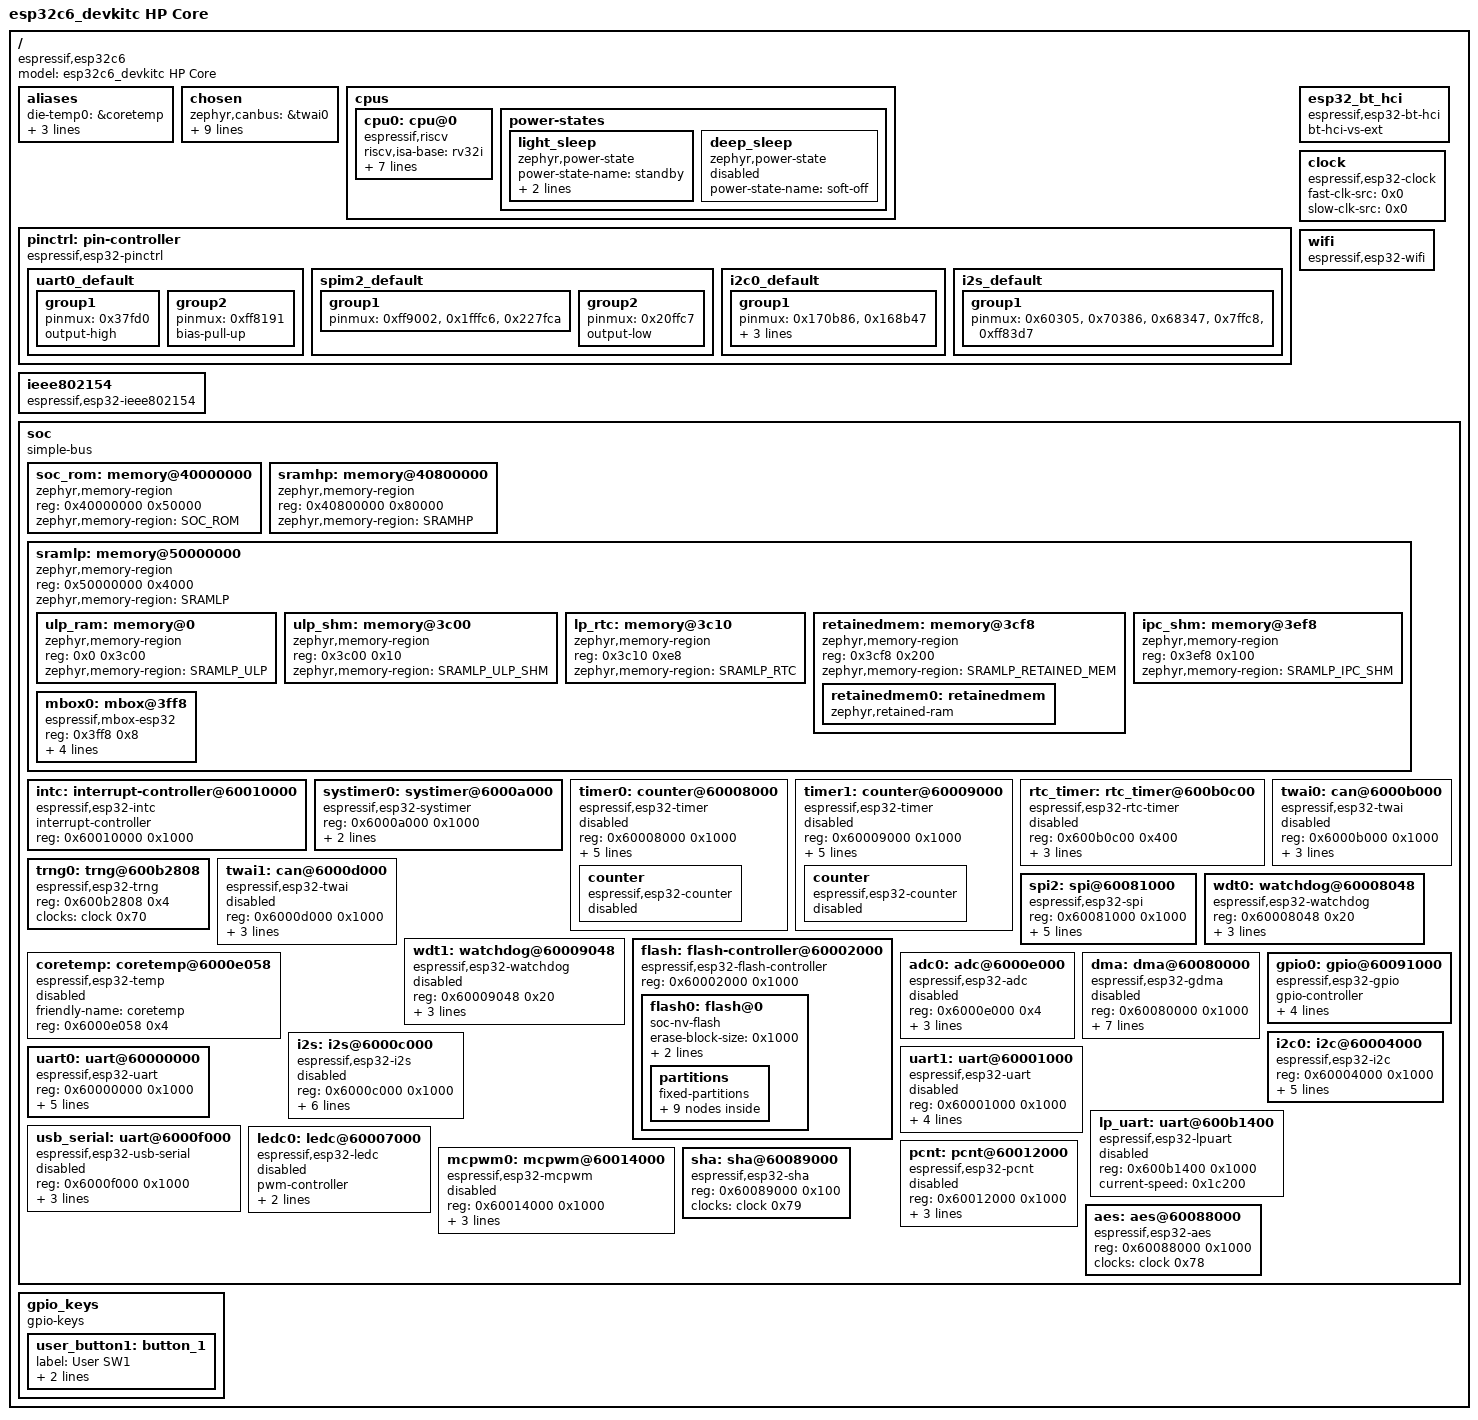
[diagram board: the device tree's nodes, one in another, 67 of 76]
/dts-v1/;

/* node '/' defined in zephyr/dts/riscv/espressif/esp32c6/esp32c6_common.dtsi:16 */
/ {
	#address-cells = < 0x1 >;          /* in zephyr/dts/riscv/espressif/esp32c6/esp32c6_common.dtsi:17 */
	#size-cells = < 0x1 >;             /* in zephyr/dts/riscv/espressif/esp32c6/esp32c6_common.dtsi:18 */
	model = "esp32c6_devkitc HP Core"; /* in zephyr/boards/espressif/esp32c6_devkitc/esp32c6_devkitc_hpcore.dts:15 */
	compatible = "espressif,esp32c6";  /* in zephyr/boards/espressif/esp32c6_devkitc/esp32c6_devkitc_hpcore.dts:16 */

	/* node '/aliases' defined in zephyr/dts/riscv/espressif/esp32c6/esp32c6_common.dtsi:20 */
	aliases {
		die-temp0 = &coretemp;             /* in zephyr/dts/riscv/espressif/esp32c6/esp32c6_common.dtsi:21 */
		retainedmemdevice = &retainedmem0; /* in zephyr/dts/riscv/espressif/esp32c6/esp32c6_common.dtsi:22 */
		sw0 = &user_button1;               /* in zephyr/boards/espressif/esp32c6_devkitc/esp32c6_devkitc_hpcore.dts:28 */
		watchdog0 = &wdt0;                 /* in zephyr/boards/espressif/esp32c6_devkitc/esp32c6_devkitc_hpcore.dts:29 */
	};

	/* node '/chosen' defined in zephyr/dts/riscv/espressif/esp32c6/esp32c6_common.dtsi:25 */
	chosen {
		zephyr,canbus = &twai0;                   /* in zephyr/dts/riscv/espressif/esp32c6/esp32c6_common.dtsi:26 */
		zephyr,entropy = &trng0;                  /* in zephyr/dts/riscv/espressif/esp32c6/esp32c6_common.dtsi:27 */
		zephyr,flash-controller = &flash;         /* in zephyr/dts/riscv/espressif/esp32c6/esp32c6_common.dtsi:28 */
		zephyr,bt-hci = &esp32_bt_hci;            /* in zephyr/dts/riscv/espressif/esp32c6/esp32c6_common.dtsi:29 */
		zephyr,sram = &sramhp;                    /* in zephyr/boards/espressif/esp32c6_devkitc/esp32c6_devkitc_hpcore.dts:19 */
		zephyr,console = &uart0;                  /* in zephyr/boards/espressif/esp32c6_devkitc/esp32c6_devkitc_hpcore.dts:20 */
		zephyr,shell-uart = &uart0;               /* in zephyr/boards/espressif/esp32c6_devkitc/esp32c6_devkitc_hpcore.dts:21 */
		zephyr,flash = &flash0;                   /* in zephyr/boards/espressif/esp32c6_devkitc/esp32c6_devkitc_hpcore.dts:22 */
		zephyr,code-partition = &slot0_partition; /* in zephyr/boards/espressif/esp32c6_devkitc/esp32c6_devkitc_hpcore.dts:23 */
		zephyr,ieee802154 = &ieee802154;          /* in zephyr/boards/espressif/esp32c6_devkitc/esp32c6_devkitc_hpcore.dts:24 */
	};

	/* node '/cpus' defined in zephyr/dts/riscv/espressif/esp32c6/esp32c6_common.dtsi:32 */
	cpus {
		#address-cells = < 0x1 >; /* in zephyr/dts/riscv/espressif/esp32c6/esp32c6_common.dtsi:33 */
		#size-cells = < 0x0 >;    /* in zephyr/dts/riscv/espressif/esp32c6/esp32c6_common.dtsi:34 */

		/* node '/cpus/cpu@0' defined in zephyr/dts/riscv/espressif/esp32c6/esp32c6_common.dtsi:36 */
		cpu0: cpu@0 {
			device_type = "cpu";                             /* in zephyr/dts/riscv/espressif/esp32c6/esp32c6_common.dtsi:37 */
			compatible = "espressif,riscv",
			             "riscv";                            /* in zephyr/dts/riscv/espressif/esp32c6/esp32c6_common.dtsi:38 */
			riscv,isa-base = "rv32i";                        /* in zephyr/dts/riscv/espressif/esp32c6/esp32c6_common.dtsi:39 */
			riscv,isa-extensions = "i",
			                       "m",
			                       "a",
			                       "c",
			                       "zicsr",
			                       "zifencei";               /* in zephyr/dts/riscv/espressif/esp32c6/esp32c6_common.dtsi:40 */
			reg = < 0x0 >;                                   /* in zephyr/dts/riscv/espressif/esp32c6/esp32c6_common.dtsi:41 */
			cpu-power-states = < &light_sleep &deep_sleep >; /* in zephyr/dts/riscv/espressif/esp32c6/esp32c6_common.dtsi:42 */
			clock-source = < 0x1 >;                          /* in zephyr/dts/riscv/espressif/esp32c6/esp32c6_common.dtsi:43 */
			clock-frequency = < 0x9896800 >;                 /* in zephyr/dts/riscv/espressif/esp32c6/esp32c6_common.dtsi:44 */
			xtal-freq = < 0x2625a00 >;                       /* in zephyr/dts/riscv/espressif/esp32c6/esp32c6_common.dtsi:45 */
		};

		/* node '/cpus/power-states' defined in zephyr/dts/riscv/espressif/esp32c6/esp32c6_common.dtsi:48 */
		power-states {

			/* node '/cpus/power-states/light_sleep' defined in zephyr/dts/riscv/espressif/esp32c6/esp32c6_common.dtsi:49 */
			light_sleep: light_sleep {
				compatible = "zephyr,power-state"; /* in zephyr/dts/riscv/espressif/esp32c6/esp32c6_common.dtsi:50 */
				power-state-name = "standby";      /* in zephyr/dts/riscv/espressif/esp32c6/esp32c6_common.dtsi:51 */
				min-residency-us = < 0x9c4 >;      /* in zephyr/dts/riscv/espressif/esp32c6/esp32c6_common.dtsi:52 */
				exit-latency-us = < 0x32 >;        /* in zephyr/dts/riscv/espressif/esp32c6/esp32c6_common.dtsi:53 */
				phandle = < 0x1 >;                 /* in zephyr/dts/riscv/espressif/esp32c6/esp32c6_common.dtsi:42 */
			};

			/* node '/cpus/power-states/deep_sleep' defined in zephyr/dts/riscv/espressif/esp32c6/esp32c6_common.dtsi:56 */
			deep_sleep: deep_sleep {
				compatible = "zephyr,power-state"; /* in zephyr/dts/riscv/espressif/esp32c6/esp32c6_common.dtsi:60 */
				power-state-name = "soft-off";     /* in zephyr/dts/riscv/espressif/esp32c6/esp32c6_common.dtsi:61 */
				status = "disabled";               /* in zephyr/dts/riscv/espressif/esp32c6/esp32c6_common.dtsi:62 */
				phandle = < 0x2 >;                 /* in zephyr/dts/riscv/espressif/esp32c6/esp32c6_common.dtsi:42 */
			};
		};
	};

	/* node '/pin-controller' defined in zephyr/dts/riscv/espressif/esp32c6/esp32c6_common.dtsi:67 */
	pinctrl: pin-controller {
		compatible = "espressif,esp32-pinctrl"; /* in zephyr/dts/riscv/espressif/esp32c6/esp32c6_common.dtsi:68 */
		status = "okay";                        /* in zephyr/dts/riscv/espressif/esp32c6/esp32c6_common.dtsi:69 */

		/* node '/pin-controller/uart0_default' defined in zephyr/boards/espressif/esp32c6_devkitc/esp32c6_devkitc_hpcore-pinctrl.dtsi:12 */
		uart0_default: uart0_default {
			phandle = < 0xa >; /* in zephyr/boards/espressif/esp32c6_devkitc/esp32c6_devkitc_hpcore.dts:46 */

			/* node '/pin-controller/uart0_default/group1' defined in zephyr/boards/espressif/esp32c6_devkitc/esp32c6_devkitc_hpcore-pinctrl.dtsi:13 */
			group1 {
				pinmux = < 0x37fd0 >; /* in zephyr/boards/espressif/esp32c6_devkitc/esp32c6_devkitc_hpcore-pinctrl.dtsi:14 */
				output-high;          /* in zephyr/boards/espressif/esp32c6_devkitc/esp32c6_devkitc_hpcore-pinctrl.dtsi:15 */
			};

			/* node '/pin-controller/uart0_default/group2' defined in zephyr/boards/espressif/esp32c6_devkitc/esp32c6_devkitc_hpcore-pinctrl.dtsi:18 */
			group2 {
				pinmux = < 0xff8191 >; /* in zephyr/boards/espressif/esp32c6_devkitc/esp32c6_devkitc_hpcore-pinctrl.dtsi:19 */
				bias-pull-up;          /* in zephyr/boards/espressif/esp32c6_devkitc/esp32c6_devkitc_hpcore-pinctrl.dtsi:20 */
			};
		};

		/* node '/pin-controller/spim2_default' defined in zephyr/boards/espressif/esp32c6_devkitc/esp32c6_devkitc_hpcore-pinctrl.dtsi:24 */
		spim2_default: spim2_default {
			phandle = < 0x6 >; /* in zephyr/boards/espressif/esp32c6_devkitc/esp32c6_devkitc_hpcore.dts:70 */

			/* node '/pin-controller/spim2_default/group1' defined in zephyr/boards/espressif/esp32c6_devkitc/esp32c6_devkitc_hpcore-pinctrl.dtsi:25 */
			group1 {
				pinmux = < 0xff9002 >,
				         < 0x1fffc6 >,
				         < 0x227fca >; /* in zephyr/boards/espressif/esp32c6_devkitc/esp32c6_devkitc_hpcore-pinctrl.dtsi:26 */
			};

			/* node '/pin-controller/spim2_default/group2' defined in zephyr/boards/espressif/esp32c6_devkitc/esp32c6_devkitc_hpcore-pinctrl.dtsi:31 */
			group2 {
				pinmux = < 0x20ffc7 >; /* in zephyr/boards/espressif/esp32c6_devkitc/esp32c6_devkitc_hpcore-pinctrl.dtsi:32 */
				output-low;            /* in zephyr/boards/espressif/esp32c6_devkitc/esp32c6_devkitc_hpcore-pinctrl.dtsi:33 */
			};
		};

		/* node '/pin-controller/i2c0_default' defined in zephyr/boards/espressif/esp32c6_devkitc/esp32c6_devkitc_hpcore-pinctrl.dtsi:37 */
		i2c0_default: i2c0_default {
			phandle = < 0x7 >; /* in zephyr/boards/espressif/esp32c6_devkitc/esp32c6_devkitc_hpcore.dts:57 */

			/* node '/pin-controller/i2c0_default/group1' defined in zephyr/boards/espressif/esp32c6_devkitc/esp32c6_devkitc_hpcore-pinctrl.dtsi:38 */
			group1 {
				pinmux = < 0x170b86 >,
				         < 0x168b47 >; /* in zephyr/boards/espressif/esp32c6_devkitc/esp32c6_devkitc_hpcore-pinctrl.dtsi:39 */
				bias-pull-up;          /* in zephyr/boards/espressif/esp32c6_devkitc/esp32c6_devkitc_hpcore-pinctrl.dtsi:41 */
				drive-open-drain;      /* in zephyr/boards/espressif/esp32c6_devkitc/esp32c6_devkitc_hpcore-pinctrl.dtsi:42 */
				output-high;           /* in zephyr/boards/espressif/esp32c6_devkitc/esp32c6_devkitc_hpcore-pinctrl.dtsi:43 */
			};
		};

		/* node '/pin-controller/i2s_default' defined in zephyr/boards/espressif/esp32c6_devkitc/esp32c6_devkitc_hpcore-pinctrl.dtsi:47 */
		i2s_default: i2s_default {
			phandle = < 0x9 >; /* in zephyr/boards/espressif/esp32c6_devkitc/esp32c6_devkitc_hpcore.dts:62 */

			/* node '/pin-controller/i2s_default/group1' defined in zephyr/boards/espressif/esp32c6_devkitc/esp32c6_devkitc_hpcore-pinctrl.dtsi:48 */
			group1 {
				pinmux = < 0x60305 >,
				         < 0x70386 >,
				         < 0x68347 >,
				         < 0x7ffc8 >,
				         < 0xff83d7 >; /* in zephyr/boards/espressif/esp32c6_devkitc/esp32c6_devkitc_hpcore-pinctrl.dtsi:49 */
			};
		};
	};

	/* node '/esp32_bt_hci' defined in zephyr/dts/riscv/espressif/esp32c6/esp32c6_common.dtsi:72 */
	esp32_bt_hci: esp32_bt_hci {
		compatible = "espressif,esp32-bt-hci"; /* in zephyr/dts/riscv/espressif/esp32c6/esp32c6_common.dtsi:73 */
		bt-hci-vs-ext;                         /* in zephyr/dts/riscv/espressif/esp32c6/esp32c6_common.dtsi:74 */
		status = "okay";                       /* in zephyr/boards/espressif/esp32c6_devkitc/esp32c6_devkitc_hpcore.dts:91 */
	};

	/* node '/clock' defined in zephyr/dts/riscv/espressif/esp32c6/esp32c6_common.dtsi:78 */
	clock: clock {
		compatible = "espressif,esp32-clock"; /* in zephyr/dts/riscv/espressif/esp32c6/esp32c6_common.dtsi:79 */
		fast-clk-src = < 0x0 >;               /* in zephyr/dts/riscv/espressif/esp32c6/esp32c6_common.dtsi:80 */
		slow-clk-src = < 0x0 >;               /* in zephyr/dts/riscv/espressif/esp32c6/esp32c6_common.dtsi:81 */
		#clock-cells = < 0x1 >;               /* in zephyr/dts/riscv/espressif/esp32c6/esp32c6_common.dtsi:82 */
		status = "okay";                      /* in zephyr/dts/riscv/espressif/esp32c6/esp32c6_common.dtsi:83 */
		phandle = < 0x5 >;                    /* in zephyr/dts/riscv/espressif/esp32c6/esp32c6_common.dtsi:202 */
	};

	/* node '/wifi' defined in zephyr/dts/riscv/espressif/esp32c6/esp32c6_common.dtsi:86 */
	wifi: wifi {
		compatible = "espressif,esp32-wifi"; /* in zephyr/dts/riscv/espressif/esp32c6/esp32c6_common.dtsi:87 */
		status = "okay";                     /* in zephyr/boards/espressif/esp32c6_devkitc/esp32c6_devkitc_hpcore.dts:83 */
	};

	/* node '/ieee802154' defined in zephyr/dts/riscv/espressif/esp32c6/esp32c6_common.dtsi:91 */
	ieee802154: ieee802154 {
		compatible = "espressif,esp32-ieee802154"; /* in zephyr/dts/riscv/espressif/esp32c6/esp32c6_common.dtsi:92 */
		status = "okay";                           /* in zephyr/boards/espressif/esp32c6_devkitc/esp32c6_devkitc_hpcore.dts:87 */
	};

	/* node '/soc' defined in zephyr/dts/riscv/espressif/esp32c6/esp32c6_common.dtsi:96 */
	soc {
		#address-cells = < 0x1 >;  /* in zephyr/dts/riscv/espressif/esp32c6/esp32c6_common.dtsi:97 */
		#size-cells = < 0x1 >;     /* in zephyr/dts/riscv/espressif/esp32c6/esp32c6_common.dtsi:98 */
		compatible = "simple-bus"; /* in zephyr/dts/riscv/espressif/esp32c6/esp32c6_common.dtsi:99 */
		ranges;                    /* in zephyr/dts/riscv/espressif/esp32c6/esp32c6_common.dtsi:100 */

		/* node '/soc/memory@40000000' defined in zephyr/dts/riscv/espressif/esp32c6/esp32c6_common.dtsi:107 */
		soc_rom: memory@40000000 {
			compatible = "zephyr,memory-region"; /* in zephyr/dts/riscv/espressif/esp32c6/esp32c6_common.dtsi:108 */
			reg = < 0x40000000 0x50000 >;        /* in zephyr/dts/riscv/espressif/esp32c6/esp32c6_common.dtsi:109 */
			zephyr,memory-region = "SOC_ROM";    /* in zephyr/dts/riscv/espressif/esp32c6/esp32c6_common.dtsi:110 */
		};

		/* node '/soc/memory@40800000' defined in zephyr/dts/riscv/espressif/esp32c6/esp32c6_common.dtsi:113 */
		sramhp: memory@40800000 {
			compatible = "zephyr,memory-region",
			             "mmio-sram";            /* in zephyr/dts/riscv/espressif/esp32c6/esp32c6_common.dtsi:114 */
			reg = < 0x40800000 0x80000 >;        /* in zephyr/dts/riscv/espressif/esp32c6/esp32c6_common.dtsi:115 */
			zephyr,memory-region = "SRAMHP";     /* in zephyr/dts/riscv/espressif/esp32c6/esp32c6_common.dtsi:116 */
		};

		/* node '/soc/memory@50000000' defined in zephyr/dts/riscv/espressif/esp32c6/esp32c6_common.dtsi:119 */
		sramlp: memory@50000000 {
			#address-cells = < 0x1 >;            /* in zephyr/dts/riscv/espressif/esp32c6/esp32c6_common.dtsi:120 */
			#size-cells = < 0x1 >;               /* in zephyr/dts/riscv/espressif/esp32c6/esp32c6_common.dtsi:121 */
			compatible = "zephyr,memory-region",
			             "mmio-sram";            /* in zephyr/dts/riscv/espressif/esp32c6/esp32c6_common.dtsi:122 */
			reg = < 0x50000000 0x4000 >;         /* in zephyr/dts/riscv/espressif/esp32c6/esp32c6_common.dtsi:123 */
			zephyr,memory-region = "SRAMLP";     /* in zephyr/dts/riscv/espressif/esp32c6/esp32c6_common.dtsi:124 */
			ranges = < 0x0 0x50000000 0x4000 >;  /* in zephyr/dts/riscv/espressif/esp32c6/esp32c6_common.dtsi:125 */

			/* node '/soc/memory@50000000/memory@0' defined in zephyr/dts/riscv/espressif/esp32c6/esp32c6_common.dtsi:127 */
			ulp_ram: memory@0 {
				compatible = "zephyr,memory-region",
				             "mmio-sram";            /* in zephyr/dts/riscv/espressif/esp32c6/esp32c6_common.dtsi:128 */
				reg = < 0x0 0x3c00 >;                /* in zephyr/dts/riscv/espressif/esp32c6/esp32c6_common.dtsi:129 */
				zephyr,memory-region = "SRAMLP_ULP"; /* in zephyr/dts/riscv/espressif/esp32c6/esp32c6_common.dtsi:130 */
			};

			/* node '/soc/memory@50000000/memory@3c00' defined in zephyr/dts/riscv/espressif/esp32c6/esp32c6_common.dtsi:133 */
			ulp_shm: memory@3c00 {
				compatible = "zephyr,memory-region",
				             "mmio-sram";                /* in zephyr/dts/riscv/espressif/esp32c6/esp32c6_common.dtsi:134 */
				reg = < 0x3c00 0x10 >;                   /* in zephyr/dts/riscv/espressif/esp32c6/esp32c6_common.dtsi:135 */
				zephyr,memory-region = "SRAMLP_ULP_SHM"; /* in zephyr/dts/riscv/espressif/esp32c6/esp32c6_common.dtsi:136 */
			};

			/* node '/soc/memory@50000000/memory@3c10' defined in zephyr/dts/riscv/espressif/esp32c6/esp32c6_common.dtsi:139 */
			lp_rtc: memory@3c10 {
				compatible = "zephyr,memory-region",
				             "mmio-sram";            /* in zephyr/dts/riscv/espressif/esp32c6/esp32c6_common.dtsi:140 */
				reg = < 0x3c10 0xe8 >;               /* in zephyr/dts/riscv/espressif/esp32c6/esp32c6_common.dtsi:141 */
				zephyr,memory-region = "SRAMLP_RTC"; /* in zephyr/dts/riscv/espressif/esp32c6/esp32c6_common.dtsi:142 */
			};

			/* node '/soc/memory@50000000/memory@3cf8' defined in zephyr/dts/riscv/espressif/esp32c6/esp32c6_common.dtsi:145 */
			retainedmem: memory@3cf8 {
				compatible = "zephyr,memory-region",
				             "mmio-sram";                     /* in zephyr/dts/riscv/espressif/esp32c6/esp32c6_common.dtsi:146 */
				reg = < 0x3cf8 0x200 >;                       /* in zephyr/dts/riscv/espressif/esp32c6/esp32c6_common.dtsi:147 */
				ranges = < 0x0 0x3cf8 0x200 >;                /* in zephyr/dts/riscv/espressif/esp32c6/esp32c6_common.dtsi:148 */
				zephyr,memory-region = "SRAMLP_RETAINED_MEM"; /* in zephyr/dts/riscv/espressif/esp32c6/esp32c6_common.dtsi:149 */
				status = "okay";                              /* in zephyr/dts/riscv/espressif/esp32c6/esp32c6_common.dtsi:150 */
				#address-cells = < 0x1 >;                     /* in zephyr/dts/riscv/espressif/esp32c6/esp32c6_common.dtsi:151 */
				#size-cells = < 0x1 >;                        /* in zephyr/dts/riscv/espressif/esp32c6/esp32c6_common.dtsi:152 */

				/* node '/soc/memory@50000000/memory@3cf8/retainedmem' defined in zephyr/dts/riscv/espressif/esp32c6/esp32c6_common.dtsi:154 */
				retainedmem0: retainedmem {
					compatible = "zephyr,retained-ram"; /* in zephyr/dts/riscv/espressif/esp32c6/esp32c6_common.dtsi:155 */
					status = "okay";                    /* in zephyr/dts/riscv/espressif/esp32c6/esp32c6_common.dtsi:156 */
					ranges;                             /* in zephyr/dts/riscv/espressif/esp32c6/esp32c6_common.dtsi:157 */
					#address-cells = < 0x1 >;           /* in zephyr/dts/riscv/espressif/esp32c6/esp32c6_common.dtsi:158 */
					#size-cells = < 0x1 >;              /* in zephyr/dts/riscv/espressif/esp32c6/esp32c6_common.dtsi:159 */
				};
			};

			/* node '/soc/memory@50000000/memory@3ef8' defined in zephyr/dts/riscv/espressif/esp32c6/esp32c6_common.dtsi:163 */
			ipc_shm: memory@3ef8 {
				compatible = "zephyr,memory-region",
				             "mmio-sram";                /* in zephyr/dts/riscv/espressif/esp32c6/esp32c6_common.dtsi:164 */
				reg = < 0x3ef8 0x100 >;                  /* in zephyr/dts/riscv/espressif/esp32c6/esp32c6_common.dtsi:165 */
				zephyr,memory-region = "SRAMLP_IPC_SHM"; /* in zephyr/dts/riscv/espressif/esp32c6/esp32c6_common.dtsi:166 */
				phandle = < 0x3 >;                       /* in zephyr/dts/riscv/espressif/esp32c6/esp32c6_common.dtsi:173 */
			};

			/* node '/soc/memory@50000000/mbox@3ff8' defined in zephyr/dts/riscv/espressif/esp32c6/esp32c6_common.dtsi:169 */
			mbox0: mbox@3ff8 {
				compatible = "espressif,mbox-esp32"; /* in zephyr/dts/riscv/espressif/esp32c6/esp32c6_common.dtsi:170 */
				reg = < 0x3ff8 0x8 >;                /* in zephyr/dts/riscv/espressif/esp32c6/esp32c6_common.dtsi:171 */
				status = "okay";                     /* in zephyr/dts/riscv/espressif/esp32c6/esp32c6_common.dtsi:172 */
				shared-memory = < &ipc_shm >;        /* in zephyr/dts/riscv/espressif/esp32c6/esp32c6_common.dtsi:173 */
				shared-memory-size = < 0x100 >;      /* in zephyr/dts/riscv/espressif/esp32c6/esp32c6_common.dtsi:174 */
				interrupts = < 0xd 0x0 0x0 >,
				             < 0x5 0x0 0x0 >;        /* in zephyr/dts/riscv/espressif/esp32c6/esp32c6_common.dtsi:175 */
				interrupt-parent = < &intc >;        /* in zephyr/dts/riscv/espressif/esp32c6/esp32c6_common.dtsi:177 */
				#mbox-cells = < 0x1 >;               /* in zephyr/dts/riscv/espressif/esp32c6/esp32c6_common.dtsi:178 */
			};
		};

		/* node '/soc/interrupt-controller@60010000' defined in zephyr/dts/riscv/espressif/esp32c6/esp32c6_common.dtsi:182 */
		intc: interrupt-controller@60010000 {
			compatible = "espressif,esp32-intc"; /* in zephyr/dts/riscv/espressif/esp32c6/esp32c6_common.dtsi:183 */
			#address-cells = < 0x0 >;            /* in zephyr/dts/riscv/espressif/esp32c6/esp32c6_common.dtsi:184 */
			#interrupt-cells = < 0x3 >;          /* in zephyr/dts/riscv/espressif/esp32c6/esp32c6_common.dtsi:185 */
			interrupt-controller;                /* in zephyr/dts/riscv/espressif/esp32c6/esp32c6_common.dtsi:186 */
			reg = < 0x60010000 0x1000 >;         /* in zephyr/dts/riscv/espressif/esp32c6/esp32c6_common.dtsi:187 */
			status = "okay";                     /* in zephyr/dts/riscv/espressif/esp32c6/esp32c6_common.dtsi:188 */
			phandle = < 0x4 >;                   /* in zephyr/dts/riscv/espressif/esp32c6/esp32c6_common.dtsi:177 */
		};

		/* node '/soc/systimer@6000a000' defined in zephyr/dts/riscv/espressif/esp32c6/esp32c6_common.dtsi:191 */
		systimer0: systimer@6000a000 {
			compatible = "espressif,esp32-systimer"; /* in zephyr/dts/riscv/espressif/esp32c6/esp32c6_common.dtsi:192 */
			reg = < 0x6000a000 0x1000 >;             /* in zephyr/dts/riscv/espressif/esp32c6/esp32c6_common.dtsi:193 */
			interrupts = < 0x39 0x0 0x0 >;           /* in zephyr/dts/riscv/espressif/esp32c6/esp32c6_common.dtsi:194 */
			interrupt-parent = < &intc >;            /* in zephyr/dts/riscv/espressif/esp32c6/esp32c6_common.dtsi:195 */
			status = "okay";                         /* in zephyr/dts/riscv/espressif/esp32c6/esp32c6_common.dtsi:196 */
		};

		/* node '/soc/counter@60008000' defined in zephyr/dts/riscv/espressif/esp32c6/esp32c6_common.dtsi:199 */
		timer0: counter@60008000 {
			compatible = "espressif,esp32-timer"; /* in zephyr/dts/riscv/espressif/esp32c6/esp32c6_common.dtsi:200 */
			reg = < 0x60008000 0x1000 >;          /* in zephyr/dts/riscv/espressif/esp32c6/esp32c6_common.dtsi:201 */
			clocks = < &clock 0x0 >;              /* in zephyr/dts/riscv/espressif/esp32c6/esp32c6_common.dtsi:202 */
			group = < 0x0 >;                      /* in zephyr/dts/riscv/espressif/esp32c6/esp32c6_common.dtsi:203 */
			index = < 0x0 >;                      /* in zephyr/dts/riscv/espressif/esp32c6/esp32c6_common.dtsi:204 */
			interrupts = < 0x33 0x0 0x0 >;        /* in zephyr/dts/riscv/espressif/esp32c6/esp32c6_common.dtsi:205 */
			interrupt-parent = < &intc >;         /* in zephyr/dts/riscv/espressif/esp32c6/esp32c6_common.dtsi:206 */
			status = "disabled";                  /* in zephyr/dts/riscv/espressif/esp32c6/esp32c6_common.dtsi:207 */

			/* node '/soc/counter@60008000/counter' defined in zephyr/dts/riscv/espressif/esp32c6/esp32c6_common.dtsi:209 */
			counter {
				compatible = "espressif,esp32-counter"; /* in zephyr/dts/riscv/espressif/esp32c6/esp32c6_common.dtsi:210 */
				status = "disabled";                    /* in zephyr/dts/riscv/espressif/esp32c6/esp32c6_common.dtsi:211 */
			};
		};

		/* node '/soc/counter@60009000' defined in zephyr/dts/riscv/espressif/esp32c6/esp32c6_common.dtsi:215 */
		timer1: counter@60009000 {
			compatible = "espressif,esp32-timer"; /* in zephyr/dts/riscv/espressif/esp32c6/esp32c6_common.dtsi:216 */
			reg = < 0x60009000 0x1000 >;          /* in zephyr/dts/riscv/espressif/esp32c6/esp32c6_common.dtsi:217 */
			clocks = < &clock 0x1 >;              /* in zephyr/dts/riscv/espressif/esp32c6/esp32c6_common.dtsi:218 */
			group = < 0x1 >;                      /* in zephyr/dts/riscv/espressif/esp32c6/esp32c6_common.dtsi:219 */
			index = < 0x0 >;                      /* in zephyr/dts/riscv/espressif/esp32c6/esp32c6_common.dtsi:220 */
			interrupts = < 0x36 0x0 0x0 >;        /* in zephyr/dts/riscv/espressif/esp32c6/esp32c6_common.dtsi:221 */
			interrupt-parent = < &intc >;         /* in zephyr/dts/riscv/espressif/esp32c6/esp32c6_common.dtsi:222 */
			status = "disabled";                  /* in zephyr/dts/riscv/espressif/esp32c6/esp32c6_common.dtsi:223 */

			/* node '/soc/counter@60009000/counter' defined in zephyr/dts/riscv/espressif/esp32c6/esp32c6_common.dtsi:225 */
			counter {
				compatible = "espressif,esp32-counter"; /* in zephyr/dts/riscv/espressif/esp32c6/esp32c6_common.dtsi:226 */
				status = "disabled";                    /* in zephyr/dts/riscv/espressif/esp32c6/esp32c6_common.dtsi:227 */
			};
		};

		/* node '/soc/rtc_timer@600b0c00' defined in zephyr/dts/riscv/espressif/esp32c6/esp32c6_common.dtsi:231 */
		rtc_timer: rtc_timer@600b0c00 {
			compatible = "espressif,esp32-rtc-timer"; /* in zephyr/dts/riscv/espressif/esp32c6/esp32c6_common.dtsi:232 */
			reg = < 0x600b0c00 0x400 >;               /* in zephyr/dts/riscv/espressif/esp32c6/esp32c6_common.dtsi:233 */
			clocks = < &clock 0xd >;                  /* in zephyr/dts/riscv/espressif/esp32c6/esp32c6_common.dtsi:234 */
			interrupts = < 0xf 0x0 0x0 >;             /* in zephyr/dts/riscv/espressif/esp32c6/esp32c6_common.dtsi:235 */
			interrupt-parent = < &intc >;             /* in zephyr/dts/riscv/espressif/esp32c6/esp32c6_common.dtsi:236 */
			status = "disabled";                      /* in zephyr/dts/riscv/espressif/esp32c6/esp32c6_common.dtsi:237 */
		};

		/* node '/soc/trng@600b2808' defined in zephyr/dts/riscv/espressif/esp32c6/esp32c6_common.dtsi:240 */
		trng0: trng@600b2808 {
			compatible = "espressif,esp32-trng"; /* in zephyr/dts/riscv/espressif/esp32c6/esp32c6_common.dtsi:241 */
			reg = < 0x600b2808 0x4 >;            /* in zephyr/dts/riscv/espressif/esp32c6/esp32c6_common.dtsi:242 */
			clocks = < &clock 0x70 >;            /* in zephyr/dts/riscv/espressif/esp32c6/esp32c6_common.dtsi:243 */
			status = "okay";                     /* in zephyr/boards/espressif/esp32c6_devkitc/esp32c6_devkitc_hpcore.dts:51 */
		};

		/* node '/soc/can@6000b000' defined in zephyr/dts/riscv/espressif/esp32c6/esp32c6_common.dtsi:247 */
		twai0: can@6000b000 {
			compatible = "espressif,esp32-twai"; /* in zephyr/dts/riscv/espressif/esp32c6/esp32c6_common.dtsi:248 */
			reg = < 0x6000b000 0x1000 >;         /* in zephyr/dts/riscv/espressif/esp32c6/esp32c6_common.dtsi:249 */
			interrupts = < 0x2e 0x0 0x0 >;       /* in zephyr/dts/riscv/espressif/esp32c6/esp32c6_common.dtsi:250 */
			interrupt-parent = < &intc >;        /* in zephyr/dts/riscv/espressif/esp32c6/esp32c6_common.dtsi:251 */
			clocks = < &clock 0x6e >;            /* in zephyr/dts/riscv/espressif/esp32c6/esp32c6_common.dtsi:252 */
			status = "disabled";                 /* in zephyr/dts/riscv/espressif/esp32c6/esp32c6_common.dtsi:253 */
		};

		/* node '/soc/can@6000d000' defined in zephyr/dts/riscv/espressif/esp32c6/esp32c6_common.dtsi:256 */
		twai1: can@6000d000 {
			compatible = "espressif,esp32-twai"; /* in zephyr/dts/riscv/espressif/esp32c6/esp32c6_common.dtsi:257 */
			reg = < 0x6000d000 0x1000 >;         /* in zephyr/dts/riscv/espressif/esp32c6/esp32c6_common.dtsi:258 */
			interrupts = < 0x2f 0x0 0x0 >;       /* in zephyr/dts/riscv/espressif/esp32c6/esp32c6_common.dtsi:259 */
			interrupt-parent = < &intc >;        /* in zephyr/dts/riscv/espressif/esp32c6/esp32c6_common.dtsi:260 */
			clocks = < &clock 0x6f >;            /* in zephyr/dts/riscv/espressif/esp32c6/esp32c6_common.dtsi:261 */
			status = "disabled";                 /* in zephyr/dts/riscv/espressif/esp32c6/esp32c6_common.dtsi:262 */
		};

		/* node '/soc/spi@60081000' defined in zephyr/dts/riscv/espressif/esp32c6/esp32c6_common.dtsi:265 */
		spi2: spi@60081000 {
			compatible = "espressif,esp32-spi"; /* in zephyr/dts/riscv/espressif/esp32c6/esp32c6_common.dtsi:266 */
			reg = < 0x60081000 0x1000 >;        /* in zephyr/dts/riscv/espressif/esp32c6/esp32c6_common.dtsi:267 */
			interrupts = < 0x48 0x0 0x0 >;      /* in zephyr/dts/riscv/espressif/esp32c6/esp32c6_common.dtsi:268 */
			interrupt-parent = < &intc >;       /* in zephyr/dts/riscv/espressif/esp32c6/esp32c6_common.dtsi:269 */
			clocks = < &clock 0x6d >;           /* in zephyr/dts/riscv/espressif/esp32c6/esp32c6_common.dtsi:270 */
			dma-host = < 0x0 >;                 /* in zephyr/dts/riscv/espressif/esp32c6/esp32c6_common.dtsi:271 */
			#address-cells = < 0x1 >;           /* in zephyr/boards/espressif/esp32c6_devkitc/esp32c6_devkitc_hpcore.dts:67 */
			#size-cells = < 0x0 >;              /* in zephyr/boards/espressif/esp32c6_devkitc/esp32c6_devkitc_hpcore.dts:68 */
			status = "okay";                    /* in zephyr/boards/espressif/esp32c6_devkitc/esp32c6_devkitc_hpcore.dts:69 */
			pinctrl-0 = < &spim2_default >;     /* in zephyr/boards/espressif/esp32c6_devkitc/esp32c6_devkitc_hpcore.dts:70 */
			pinctrl-names = "default";          /* in zephyr/boards/espressif/esp32c6_devkitc/esp32c6_devkitc_hpcore.dts:71 */
		};

		/* node '/soc/watchdog@60008048' defined in zephyr/dts/riscv/espressif/esp32c6/esp32c6_common.dtsi:275 */
		wdt0: watchdog@60008048 {
			compatible = "espressif,esp32-watchdog"; /* in zephyr/dts/riscv/espressif/esp32c6/esp32c6_common.dtsi:276 */
			reg = < 0x60008048 0x20 >;               /* in zephyr/dts/riscv/espressif/esp32c6/esp32c6_common.dtsi:277 */
			interrupts = < 0x35 0x0 0x0 >;           /* in zephyr/dts/riscv/espressif/esp32c6/esp32c6_common.dtsi:278 */
			interrupt-parent = < &intc >;            /* in zephyr/dts/riscv/espressif/esp32c6/esp32c6_common.dtsi:279 */
			clocks = < &clock 0x0 >;                 /* in zephyr/dts/riscv/espressif/esp32c6/esp32c6_common.dtsi:280 */
			status = "okay";                         /* in zephyr/boards/espressif/esp32c6_devkitc/esp32c6_devkitc_hpcore.dts:79 */
		};

		/* node '/soc/watchdog@60009048' defined in zephyr/dts/riscv/espressif/esp32c6/esp32c6_common.dtsi:284 */
		wdt1: watchdog@60009048 {
			compatible = "espressif,esp32-watchdog"; /* in zephyr/dts/riscv/espressif/esp32c6/esp32c6_common.dtsi:285 */
			reg = < 0x60009048 0x20 >;               /* in zephyr/dts/riscv/espressif/esp32c6/esp32c6_common.dtsi:286 */
			interrupts = < 0x38 0x0 0x0 >;           /* in zephyr/dts/riscv/espressif/esp32c6/esp32c6_common.dtsi:287 */
			interrupt-parent = < &intc >;            /* in zephyr/dts/riscv/espressif/esp32c6/esp32c6_common.dtsi:288 */
			clocks = < &clock 0x1 >;                 /* in zephyr/dts/riscv/espressif/esp32c6/esp32c6_common.dtsi:289 */
			status = "disabled";                     /* in zephyr/dts/riscv/espressif/esp32c6/esp32c6_common.dtsi:290 */
		};

		/* node '/soc/flash-controller@60002000' defined in zephyr/dts/riscv/espressif/esp32c6/esp32c6_common.dtsi:293 */
		flash: flash-controller@60002000 {
			compatible = "espressif,esp32-flash-controller"; /* in zephyr/dts/riscv/espressif/esp32c6/esp32c6_common.dtsi:294 */
			reg = < 0x60002000 0x1000 >;                     /* in zephyr/dts/riscv/espressif/esp32c6/esp32c6_common.dtsi:295 */
			#address-cells = < 0x1 >;                        /* in zephyr/dts/riscv/espressif/esp32c6/esp32c6_common.dtsi:297 */
			#size-cells = < 0x1 >;                           /* in zephyr/dts/riscv/espressif/esp32c6/esp32c6_common.dtsi:298 */

			/* node '/soc/flash-controller@60002000/flash@0' defined in zephyr/dts/riscv/espressif/esp32c6/esp32c6_common.dtsi:300 */
			flash0: flash@0 {
				compatible = "soc-nv-flash";   /* in zephyr/dts/riscv/espressif/esp32c6/esp32c6_common.dtsi:301 */
				erase-block-size = < 0x1000 >; /* in zephyr/dts/riscv/espressif/esp32c6/esp32c6_common.dtsi:302 */
				write-block-size = < 0x4 >;    /* in zephyr/dts/riscv/espressif/esp32c6/esp32c6_common.dtsi:303 */
				reg = < 0x0 0x800000 >;        /* in zephyr/dts/riscv/espressif/esp32c6/esp32c6_wroom_n8.dtsi:11 */

				/* node '/soc/flash-controller@60002000/flash@0/partitions' defined in zephyr/dts/vendor/espressif/partitions_0x0_default_4M.dtsi:8 */
				partitions {
					compatible = "fixed-partitions"; /* in zephyr/dts/vendor/espressif/partitions_0x0_default_4M.dtsi:9 */
					#address-cells = < 0x1 >;        /* in zephyr/dts/vendor/espressif/partitions_0x0_default_4M.dtsi:10 */
					#size-cells = < 0x1 >;           /* in zephyr/dts/vendor/espressif/partitions_0x0_default_4M.dtsi:11 */

					/* node '/soc/flash-controller@60002000/flash@0/partitions/partition@0' defined in zephyr/dts/vendor/espressif/partitions_0x0_default_4M.dtsi:13 */
					boot_partition: partition@0 {
						label = "mcuboot";     /* in zephyr/dts/vendor/espressif/partitions_0x0_default_4M.dtsi:14 */
						reg = < 0x0 0x10000 >; /* in zephyr/dts/vendor/espressif/partitions_0x0_default_4M.dtsi:15 */
					};

					/* node '/soc/flash-controller@60002000/flash@0/partitions/partition@10000' defined in zephyr/dts/vendor/espressif/partitions_0x0_default_4M.dtsi:18 */
					sys_partition: partition@10000 {
						label = "sys";             /* in zephyr/dts/vendor/espressif/partitions_0x0_default_4M.dtsi:19 */
						reg = < 0x10000 0x10000 >; /* in zephyr/dts/vendor/espressif/partitions_0x0_default_4M.dtsi:20 */
					};

					/* node '/soc/flash-controller@60002000/flash@0/partitions/partition@20000' defined in zephyr/dts/vendor/espressif/partitions_0x0_default_4M.dtsi:23 */
					slot0_partition: partition@20000 {
						label = "image-0";          /* in zephyr/dts/vendor/espressif/partitions_0x0_default_4M.dtsi:24 */
						reg = < 0x20000 0x1c0000 >; /* in zephyr/dts/vendor/espressif/partitions_0x0_default_4M.dtsi:25 */
					};

					/* node '/soc/flash-controller@60002000/flash@0/partitions/partition@1e0000' defined in zephyr/dts/vendor/espressif/partitions_0x0_default_4M.dtsi:28 */
					slot1_partition: partition@1e0000 {
						label = "image-1";           /* in zephyr/dts/vendor/espressif/partitions_0x0_default_4M.dtsi:29 */
						reg = < 0x1e0000 0x1c0000 >; /* in zephyr/dts/vendor/espressif/partitions_0x0_default_4M.dtsi:30 */
					};

					/* node '/soc/flash-controller@60002000/flash@0/partitions/partition@3a0000' defined in zephyr/dts/vendor/espressif/partitions_0x0_default_4M.dtsi:33 */
					slot0_lpcore_partition: partition@3a0000 {
						label = "image-0-lpcore";  /* in zephyr/dts/vendor/espressif/partitions_0x0_default_4M.dtsi:34 */
						reg = < 0x3a0000 0x8000 >; /* in zephyr/dts/vendor/espressif/partitions_0x0_default_4M.dtsi:35 */
					};

					/* node '/soc/flash-controller@60002000/flash@0/partitions/partition@3a8000' defined in zephyr/dts/vendor/espressif/partitions_0x0_default_4M.dtsi:38 */
					slot1_lpcore_partition: partition@3a8000 {
						label = "image-1-lpcore";  /* in zephyr/dts/vendor/espressif/partitions_0x0_default_4M.dtsi:39 */
						reg = < 0x3a8000 0x8000 >; /* in zephyr/dts/vendor/espressif/partitions_0x0_default_4M.dtsi:40 */
					};

					/* node '/soc/flash-controller@60002000/flash@0/partitions/partition@3b0000' defined in zephyr/dts/vendor/espressif/partitions_0x0_default_4M.dtsi:43 */
					storage_partition: partition@3b0000 {
						label = "storage";          /* in zephyr/dts/vendor/espressif/partitions_0x0_default_4M.dtsi:44 */
						reg = < 0x3b0000 0x30000 >; /* in zephyr/dts/vendor/espressif/partitions_0x0_default_4M.dtsi:45 */
					};

					/* node '/soc/flash-controller@60002000/flash@0/partitions/partition@3e0000' defined in zephyr/dts/vendor/espressif/partitions_0x0_default_4M.dtsi:48 */
					scratch_partition: partition@3e0000 {
						label = "image-scratch";    /* in zephyr/dts/vendor/espressif/partitions_0x0_default_4M.dtsi:49 */
						reg = < 0x3e0000 0x1f000 >; /* in zephyr/dts/vendor/espressif/partitions_0x0_default_4M.dtsi:50 */
					};

					/* node '/soc/flash-controller@60002000/flash@0/partitions/partition@3ff000' defined in zephyr/dts/vendor/espressif/partitions_0x0_default_4M.dtsi:53 */
					coredump_partition: partition@3ff000 {
						label = "coredump";        /* in zephyr/dts/vendor/espressif/partitions_0x0_default_4M.dtsi:54 */
						reg = < 0x3ff000 0x1000 >; /* in zephyr/dts/vendor/espressif/partitions_0x0_default_4M.dtsi:55 */
					};
				};
			};
		};

		/* node '/soc/coretemp@6000e058' defined in zephyr/dts/riscv/espressif/esp32c6/esp32c6_common.dtsi:308 */
		coretemp: coretemp@6000e058 {
			compatible = "espressif,esp32-temp"; /* in zephyr/dts/riscv/espressif/esp32c6/esp32c6_common.dtsi:309 */
			friendly-name = "coretemp";          /* in zephyr/dts/riscv/espressif/esp32c6/esp32c6_common.dtsi:310 */
			reg = < 0x6000e058 0x4 >;            /* in zephyr/dts/riscv/espressif/esp32c6/esp32c6_common.dtsi:311 */
			status = "disabled";                 /* in zephyr/dts/riscv/espressif/esp32c6/esp32c6_common.dtsi:312 */
		};

		/* node '/soc/adc@6000e000' defined in zephyr/dts/riscv/espressif/esp32c6/esp32c6_common.dtsi:315 */
		adc0: adc@6000e000 {
			compatible = "espressif,esp32-adc"; /* in zephyr/dts/riscv/espressif/esp32c6/esp32c6_common.dtsi:316 */
			reg = < 0x6000e000 0x4 >;           /* in zephyr/dts/riscv/espressif/esp32c6/esp32c6_common.dtsi:317 */
			clocks = < &clock 0x76 >;           /* in zephyr/dts/riscv/espressif/esp32c6/esp32c6_common.dtsi:318 */
			unit = < 0x1 >;                     /* in zephyr/dts/riscv/espressif/esp32c6/esp32c6_common.dtsi:319 */
			channel-count = < 0x7 >;            /* in zephyr/dts/riscv/espressif/esp32c6/esp32c6_common.dtsi:320 */
			#io-channel-cells = < 0x1 >;        /* in zephyr/dts/riscv/espressif/esp32c6/esp32c6_common.dtsi:321 */
			status = "disabled";                /* in zephyr/dts/riscv/espressif/esp32c6/esp32c6_common.dtsi:322 */
		};

		/* node '/soc/dma@60080000' defined in zephyr/dts/riscv/espressif/esp32c6/esp32c6_common.dtsi:325 */
		dma: dma@60080000 {
			compatible = "espressif,esp32-gdma"; /* in zephyr/dts/riscv/espressif/esp32c6/esp32c6_common.dtsi:326 */
			reg = < 0x60080000 0x1000 >;         /* in zephyr/dts/riscv/espressif/esp32c6/esp32c6_common.dtsi:327 */
			#dma-cells = < 0x1 >;                /* in zephyr/dts/riscv/espressif/esp32c6/esp32c6_common.dtsi:328 */
			interrupts = < 0x42 0x0 0x0 >,
			             < 0x45 0x0 0x0 >,
			             < 0x43 0x0 0x0 >,
			             < 0x46 0x0 0x0 >,
			             < 0x44 0x0 0x0 >,
			             < 0x47 0x0 0x0 >;       /* in zephyr/dts/riscv/espressif/esp32c6/esp32c6_common.dtsi:329 */
			interrupt-parent = < &intc >;        /* in zephyr/dts/riscv/espressif/esp32c6/esp32c6_common.dtsi:335 */
			clocks = < &clock 0x71 >;            /* in zephyr/dts/riscv/espressif/esp32c6/esp32c6_common.dtsi:336 */
			dma-channels = < 0x6 >;              /* in zephyr/dts/riscv/espressif/esp32c6/esp32c6_common.dtsi:337 */
			dma-buf-addr-alignment = < 0x4 >;    /* in zephyr/dts/riscv/espressif/esp32c6/esp32c6_common.dtsi:338 */
			status = "disabled";                 /* in zephyr/dts/riscv/espressif/esp32c6/esp32c6_common.dtsi:339 */
			phandle = < 0x8 >;                   /* in zephyr/dts/riscv/espressif/esp32c6/esp32c6_common.dtsi:371 */
		};

		/* node '/soc/gpio@60091000' defined in zephyr/dts/riscv/espressif/esp32c6/esp32c6_common.dtsi:342 */
		gpio0: gpio@60091000 {
			compatible = "espressif,esp32-gpio"; /* in zephyr/dts/riscv/espressif/esp32c6/esp32c6_common.dtsi:343 */
			gpio-controller;                     /* in zephyr/dts/riscv/espressif/esp32c6/esp32c6_common.dtsi:344 */
			#gpio-cells = < 0x2 >;               /* in zephyr/dts/riscv/espressif/esp32c6/esp32c6_common.dtsi:345 */
			reg = < 0x60091000 0x1000 >;         /* in zephyr/dts/riscv/espressif/esp32c6/esp32c6_common.dtsi:346 */
			interrupts = < 0x1e 0x0 0x0 >;       /* in zephyr/dts/riscv/espressif/esp32c6/esp32c6_common.dtsi:347 */
			interrupt-parent = < &intc >;        /* in zephyr/dts/riscv/espressif/esp32c6/esp32c6_common.dtsi:348 */
			ngpios = < 0x1e >;                   /* in zephyr/dts/riscv/espressif/esp32c6/esp32c6_common.dtsi:349 */
			status = "okay";                     /* in zephyr/boards/espressif/esp32c6_devkitc/esp32c6_devkitc_hpcore.dts:75 */
			phandle = < 0xb >;                   /* in zephyr/boards/espressif/esp32c6_devkitc/esp32c6_devkitc_hpcore.dts:37 */
		};

		/* node '/soc/i2c@60004000' defined in zephyr/dts/riscv/espressif/esp32c6/esp32c6_common.dtsi:352 */
		i2c0: i2c@60004000 {
			compatible = "espressif,esp32-i2c"; /* in zephyr/dts/riscv/espressif/esp32c6/esp32c6_common.dtsi:353 */
			#address-cells = < 0x1 >;           /* in zephyr/dts/riscv/espressif/esp32c6/esp32c6_common.dtsi:354 */
			#size-cells = < 0x0 >;              /* in zephyr/dts/riscv/espressif/esp32c6/esp32c6_common.dtsi:355 */
			reg = < 0x60004000 0x1000 >;        /* in zephyr/dts/riscv/espressif/esp32c6/esp32c6_common.dtsi:356 */
			interrupts = < 0x32 0x0 0x0 >;      /* in zephyr/dts/riscv/espressif/esp32c6/esp32c6_common.dtsi:357 */
			interrupt-parent = < &intc >;       /* in zephyr/dts/riscv/espressif/esp32c6/esp32c6_common.dtsi:358 */
			clocks = < &clock 0x68 >;           /* in zephyr/dts/riscv/espressif/esp32c6/esp32c6_common.dtsi:359 */
			status = "okay";                    /* in zephyr/boards/espressif/esp32c6_devkitc/esp32c6_devkitc_hpcore.dts:55 */
			clock-frequency = < 0x61a80 >;      /* in zephyr/boards/espressif/esp32c6_devkitc/esp32c6_devkitc_hpcore.dts:56 */
			pinctrl-0 = < &i2c0_default >;      /* in zephyr/boards/espressif/esp32c6_devkitc/esp32c6_devkitc_hpcore.dts:57 */
			pinctrl-names = "default";          /* in zephyr/boards/espressif/esp32c6_devkitc/esp32c6_devkitc_hpcore.dts:58 */
		};

		/* node '/soc/i2s@6000c000' defined in zephyr/dts/riscv/espressif/esp32c6/esp32c6_common.dtsi:363 */
		i2s: i2s@6000c000 {
			compatible = "espressif,esp32-i2s"; /* in zephyr/dts/riscv/espressif/esp32c6/esp32c6_common.dtsi:364 */
			#address-cells = < 0x1 >;           /* in zephyr/dts/riscv/espressif/esp32c6/esp32c6_common.dtsi:365 */
			#size-cells = < 0x0 >;              /* in zephyr/dts/riscv/espressif/esp32c6/esp32c6_common.dtsi:366 */
			reg = < 0x6000c000 0x1000 >;        /* in zephyr/dts/riscv/espressif/esp32c6/esp32c6_common.dtsi:367 */
			interrupts = < 0x29 0x0 0x0 >;      /* in zephyr/dts/riscv/espressif/esp32c6/esp32c6_common.dtsi:368 */
			interrupt-parent = < &intc >;       /* in zephyr/dts/riscv/espressif/esp32c6/esp32c6_common.dtsi:369 */
			clocks = < &clock 0x69 >;           /* in zephyr/dts/riscv/espressif/esp32c6/esp32c6_common.dtsi:370 */
			dmas = < &dma 0x2 >,
			       < &dma 0x3 >;                /* in zephyr/dts/riscv/espressif/esp32c6/esp32c6_common.dtsi:371 */
			dma-names = "rx",
			            "tx";                   /* in zephyr/dts/riscv/espressif/esp32c6/esp32c6_common.dtsi:372 */
			unit = < 0x0 >;                     /* in zephyr/dts/riscv/espressif/esp32c6/esp32c6_common.dtsi:373 */
			status = "disabled";                /* in zephyr/dts/riscv/espressif/esp32c6/esp32c6_common.dtsi:374 */
			pinctrl-0 = < &i2s_default >;       /* in zephyr/boards/espressif/esp32c6_devkitc/esp32c6_devkitc_hpcore.dts:62 */
			pinctrl-names = "default";          /* in zephyr/boards/espressif/esp32c6_devkitc/esp32c6_devkitc_hpcore.dts:63 */
		};

		/* node '/soc/uart@60000000' defined in zephyr/dts/riscv/espressif/esp32c6/esp32c6_common.dtsi:377 */
		uart0: uart@60000000 {
			compatible = "espressif,esp32-uart"; /* in zephyr/dts/riscv/espressif/esp32c6/esp32c6_common.dtsi:378 */
			reg = < 0x60000000 0x1000 >;         /* in zephyr/dts/riscv/espressif/esp32c6/esp32c6_common.dtsi:379 */
			interrupts = < 0x2b 0x0 0x0 >;       /* in zephyr/dts/riscv/espressif/esp32c6/esp32c6_common.dtsi:381 */
			interrupt-parent = < &intc >;        /* in zephyr/dts/riscv/espressif/esp32c6/esp32c6_common.dtsi:382 */
			clocks = < &clock 0x65 >;            /* in zephyr/dts/riscv/espressif/esp32c6/esp32c6_common.dtsi:383 */
			status = "okay";                     /* in zephyr/boards/espressif/esp32c6_devkitc/esp32c6_devkitc_hpcore.dts:44 */
			current-speed = < 0x1c200 >;         /* in zephyr/boards/espressif/esp32c6_devkitc/esp32c6_devkitc_hpcore.dts:45 */
			pinctrl-0 = < &uart0_default >;      /* in zephyr/boards/espressif/esp32c6_devkitc/esp32c6_devkitc_hpcore.dts:46 */
			pinctrl-names = "default";           /* in zephyr/boards/espressif/esp32c6_devkitc/esp32c6_devkitc_hpcore.dts:47 */
		};

		/* node '/soc/uart@60001000' defined in zephyr/dts/riscv/espressif/esp32c6/esp32c6_common.dtsi:386 */
		uart1: uart@60001000 {
			compatible = "espressif,esp32-uart"; /* in zephyr/dts/riscv/espressif/esp32c6/esp32c6_common.dtsi:387 */
			reg = < 0x60001000 0x1000 >;         /* in zephyr/dts/riscv/espressif/esp32c6/esp32c6_common.dtsi:388 */
			status = "disabled";                 /* in zephyr/dts/riscv/espressif/esp32c6/esp32c6_common.dtsi:389 */
			interrupts = < 0x2c 0x0 0x0 >;       /* in zephyr/dts/riscv/espressif/esp32c6/esp32c6_common.dtsi:390 */
			interrupt-parent = < &intc >;        /* in zephyr/dts/riscv/espressif/esp32c6/esp32c6_common.dtsi:391 */
			clocks = < &clock 0x66 >;            /* in zephyr/dts/riscv/espressif/esp32c6/esp32c6_common.dtsi:392 */
			current-speed = < 0x1c200 >;         /* in zephyr/dts/riscv/espressif/esp32c6/esp32c6_common.dtsi:393 */
		};

		/* node '/soc/uart@600b1400' defined in zephyr/dts/riscv/espressif/esp32c6/esp32c6_common.dtsi:396 */
		lp_uart: uart@600b1400 {
			compatible = "espressif,esp32-lpuart"; /* in zephyr/dts/riscv/espressif/esp32c6/esp32c6_common.dtsi:397 */
			reg = < 0x600b1400 0x1000 >;           /* in zephyr/dts/riscv/espressif/esp32c6/esp32c6_common.dtsi:398 */
			status = "disabled";                   /* in zephyr/dts/riscv/espressif/esp32c6/esp32c6_common.dtsi:399 */
			current-speed = < 0x1c200 >;           /* in zephyr/dts/riscv/espressif/esp32c6/esp32c6_common.dtsi:400 */
		};

		/* node '/soc/uart@6000f000' defined in zephyr/dts/riscv/espressif/esp32c6/esp32c6_common.dtsi:403 */
		usb_serial: uart@6000f000 {
			compatible = "espressif,esp32-usb-serial"; /* in zephyr/dts/riscv/espressif/esp32c6/esp32c6_common.dtsi:404 */
			reg = < 0x6000f000 0x1000 >;               /* in zephyr/dts/riscv/espressif/esp32c6/esp32c6_common.dtsi:405 */
			status = "disabled";                       /* in zephyr/dts/riscv/espressif/esp32c6/esp32c6_common.dtsi:406 */
			interrupts = < 0x30 0x0 0x0 >;             /* in zephyr/dts/riscv/espressif/esp32c6/esp32c6_common.dtsi:407 */
			interrupt-parent = < &intc >;              /* in zephyr/dts/riscv/espressif/esp32c6/esp32c6_common.dtsi:408 */
			clocks = < &clock 0x67 >;                  /* in zephyr/dts/riscv/espressif/esp32c6/esp32c6_common.dtsi:409 */
		};

		/* node '/soc/ledc@60007000' defined in zephyr/dts/riscv/espressif/esp32c6/esp32c6_common.dtsi:412 */
		ledc0: ledc@60007000 {
			compatible = "espressif,esp32-ledc"; /* in zephyr/dts/riscv/espressif/esp32c6/esp32c6_common.dtsi:413 */
			pwm-controller;                      /* in zephyr/dts/riscv/espressif/esp32c6/esp32c6_common.dtsi:414 */
			#pwm-cells = < 0x3 >;                /* in zephyr/dts/riscv/espressif/esp32c6/esp32c6_common.dtsi:415 */
			reg = < 0x60007000 0x1000 >;         /* in zephyr/dts/riscv/espressif/esp32c6/esp32c6_common.dtsi:416 */
			clocks = < &clock 0x64 >;            /* in zephyr/dts/riscv/espressif/esp32c6/esp32c6_common.dtsi:417 */
			status = "disabled";                 /* in zephyr/dts/riscv/espressif/esp32c6/esp32c6_common.dtsi:418 */
		};

		/* node '/soc/mcpwm@60014000' defined in zephyr/dts/riscv/espressif/esp32c6/esp32c6_common.dtsi:421 */
		mcpwm0: mcpwm@60014000 {
			compatible = "espressif,esp32-mcpwm"; /* in zephyr/dts/riscv/espressif/esp32c6/esp32c6_common.dtsi:422 */
			reg = < 0x60014000 0x1000 >;          /* in zephyr/dts/riscv/espressif/esp32c6/esp32c6_common.dtsi:423 */
			interrupts = < 0x3d 0x0 0x0 >;        /* in zephyr/dts/riscv/espressif/esp32c6/esp32c6_common.dtsi:424 */
			interrupt-parent = < &intc >;         /* in zephyr/dts/riscv/espressif/esp32c6/esp32c6_common.dtsi:425 */
			clocks = < &clock 0x72 >;             /* in zephyr/dts/riscv/espressif/esp32c6/esp32c6_common.dtsi:426 */
			#pwm-cells = < 0x3 >;                 /* in zephyr/dts/riscv/espressif/esp32c6/esp32c6_common.dtsi:427 */
			status = "disabled";                  /* in zephyr/dts/riscv/espressif/esp32c6/esp32c6_common.dtsi:428 */
		};

		/* node '/soc/pcnt@60012000' defined in zephyr/dts/riscv/espressif/esp32c6/esp32c6_common.dtsi:431 */
		pcnt: pcnt@60012000 {
			compatible = "espressif,esp32-pcnt"; /* in zephyr/dts/riscv/espressif/esp32c6/esp32c6_common.dtsi:432 */
			reg = < 0x60012000 0x1000 >;         /* in zephyr/dts/riscv/espressif/esp32c6/esp32c6_common.dtsi:433 */
			interrupts = < 0x3e 0x0 0x0 >;       /* in zephyr/dts/riscv/espressif/esp32c6/esp32c6_common.dtsi:434 */
			interrupt-parent = < &intc >;        /* in zephyr/dts/riscv/espressif/esp32c6/esp32c6_common.dtsi:435 */
			clocks = < &clock 0x6b >;            /* in zephyr/dts/riscv/espressif/esp32c6/esp32c6_common.dtsi:436 */
			status = "disabled";                 /* in zephyr/dts/riscv/espressif/esp32c6/esp32c6_common.dtsi:437 */
		};

		/* node '/soc/sha@60089000' defined in zephyr/dts/riscv/espressif/esp32c6/esp32c6_common.dtsi:440 */
		sha: sha@60089000 {
			compatible = "espressif,esp32-sha"; /* in zephyr/dts/riscv/espressif/esp32c6/esp32c6_common.dtsi:441 */
			reg = < 0x60089000 0x100 >;         /* in zephyr/dts/riscv/espressif/esp32c6/esp32c6_common.dtsi:442 */
			clocks = < &clock 0x79 >;           /* in zephyr/dts/riscv/espressif/esp32c6/esp32c6_common.dtsi:443 */
			status = "okay";                    /* in zephyr/dts/riscv/espressif/esp32c6/esp32c6_common.dtsi:444 */
		};

		/* node '/soc/aes@60088000' defined in zephyr/dts/riscv/espressif/esp32c6/esp32c6_common.dtsi:447 */
		aes: aes@60088000 {
			compatible = "espressif,esp32-aes"; /* in zephyr/dts/riscv/espressif/esp32c6/esp32c6_common.dtsi:448 */
			reg = < 0x60088000 0x1000 >;        /* in zephyr/dts/riscv/espressif/esp32c6/esp32c6_common.dtsi:449 */
			clocks = < &clock 0x78 >;           /* in zephyr/dts/riscv/espressif/esp32c6/esp32c6_common.dtsi:450 */
			status = "okay";                    /* in zephyr/dts/riscv/espressif/esp32c6/esp32c6_common.dtsi:451 */
		};
	};

	/* node '/gpio_keys' defined in zephyr/boards/espressif/esp32c6_devkitc/esp32c6_devkitc_hpcore.dts:32 */
	gpio_keys {
		compatible = "gpio-keys"; /* in zephyr/boards/espressif/esp32c6_devkitc/esp32c6_devkitc_hpcore.dts:33 */

		/* node '/gpio_keys/button_1' defined in zephyr/boards/espressif/esp32c6_devkitc/esp32c6_devkitc_hpcore.dts:35 */
		user_button1: button_1 {
			label = "User SW1";          /* in zephyr/boards/espressif/esp32c6_devkitc/esp32c6_devkitc_hpcore.dts:36 */
			gpios = < &gpio0 0x9 0x11 >; /* in zephyr/boards/espressif/esp32c6_devkitc/esp32c6_devkitc_hpcore.dts:37 */
			zephyr,code = < 0xb >;       /* in zephyr/boards/espressif/esp32c6_devkitc/esp32c6_devkitc_hpcore.dts:38 */
		};
	};
};
